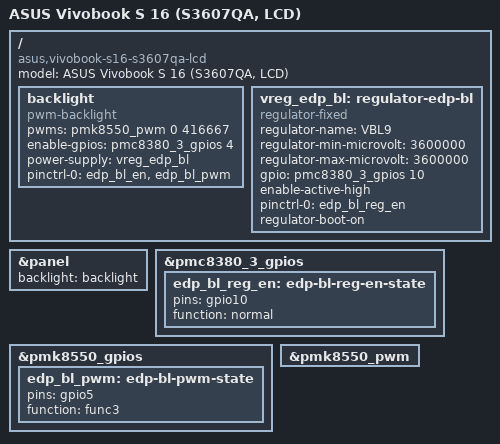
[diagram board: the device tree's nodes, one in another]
// SPDX-License-Identifier: BSD-3-Clause
/*
 * Copyright (c) 2025 Qualcomm Innovation Center, Inc. All rights reserved.
 * Copyright (c) 2025 Aleksandrs Vinarskis <alex@vinarskis.com>
 *
 * ASUS Vivobook S 16 (S3607QA) with the BOE NE160QDM-NX4 LCD panel.
 * The backlight is the Zenbook A14 LCD's, since the DSDT
 * gives this panel PMIC PWM backlight, 12 bits at 2400 Hz, as on that laptop.
 */

/dts-v1/;

#include "x1p42100-asus-vivobook-s16.dtsi"

/ {
	model = "ASUS Vivobook S 16 (S3607QA, LCD)";
	compatible = "asus,vivobook-s16-s3607qa-lcd", "asus,vivobook-s16-s3607qa", "qcom,x1p42100";

	backlight: backlight {
		compatible = "pwm-backlight";
		pwms = <&pmk8550_pwm 0 416667>;
		enable-gpios = <&pmc8380_3_gpios 4 GPIO_ACTIVE_HIGH>;
		power-supply = <&vreg_edp_bl>;

		pinctrl-0 = <&edp_bl_en>, <&edp_bl_pwm>;
		pinctrl-names = "default";
	};

	vreg_edp_bl: regulator-edp-bl {
		compatible = "regulator-fixed";

		regulator-name = "VBL9";
		regulator-min-microvolt = <3600000>;
		regulator-max-microvolt = <3600000>;

		gpio = <&pmc8380_3_gpios 10 GPIO_ACTIVE_HIGH>;
		enable-active-high;

		pinctrl-0 = <&edp_bl_reg_en>;
		pinctrl-names = "default";

		regulator-boot-on;
	};
};

&panel {
	backlight = <&backlight>;
};

&pmc8380_3_gpios {
	edp_bl_reg_en: edp-bl-reg-en-state {
		pins = "gpio10";
		function = "normal";
	};
};

&pmk8550_gpios {
	edp_bl_pwm: edp-bl-pwm-state {
		pins = "gpio5";
		function = "func3";
	};
};

&pmk8550_pwm {
	status = "okay";
};
